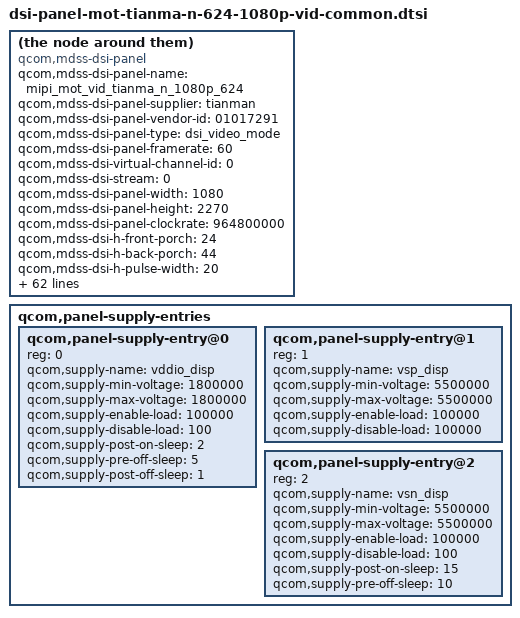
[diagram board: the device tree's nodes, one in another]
/* Copyright (c) 2016, The Linux Foundation. All rights reserved.
 *
 * This program is free software; you can redistribute it and/or modify
 * it under the terms of the GNU General Public License version 2 and
 * only version 2 as published by the Free Software Foundation.
 *
 * This program is distributed in the hope that it will be useful,
 * but WITHOUT ANY WARRANTY; without even the implied warranty of
 * MERCHANTABILITY or FITNESS FOR A PARTICULAR PURPOSE.  See the
 * GNU General Public License for more details.
 */

compatible = "qcom,mdss-dsi-panel";
qcom,mdss-dsi-panel-name = "mipi_mot_vid_tianma_n_1080p_624";
qcom,mdss-dsi-panel-supplier = "tianman";
qcom,mdss-dsi-panel-vendor-id = "01017291";
qcom,mdss-dsi-panel-type = "dsi_video_mode";
qcom,mdss-dsi-panel-framerate = <60>;
qcom,mdss-dsi-virtual-channel-id = <0>;
qcom,mdss-dsi-stream = <0>;
qcom,mdss-dsi-panel-width = <1080>;
qcom,mdss-dsi-panel-height = <2270>;
qcom,mdss-dsi-panel-clockrate = <964800000>;
qcom,mdss-dsi-h-front-porch = <24>;
qcom,mdss-dsi-h-back-porch = <44>;
qcom,mdss-dsi-h-pulse-width = <20>;
qcom,mdss-dsi-h-sync-skew = <0>;
qcom,mdss-dsi-v-front-porch = <14>;
qcom,mdss-dsi-v-back-porch = <8>;
qcom,mdss-dsi-v-pulse-width = <2>;
qcom,mdss-dsi-h-left-border = <0>;
qcom,mdss-dsi-h-right-border = <0>;
qcom,mdss-dsi-v-top-border = <0>;
qcom,mdss-dsi-v-bottom-border = <0>;
qcom,mdss-dsi-bpp = <24>;
qcom,mdss-dsi-underflow-color = <0xff>;
qcom,mdss-dsi-border-color = <0>;
qcom,mdss-dsi-on-command = [
	15 00 00 00 00 00 02 FF 23
	15 00 00 00 00 00 02 FB 01
        //resolution 1080*2270
	15 00 00 00 00 00 02 11 01
	15 00 00 00 00 00 02 12 7F
	15 00 00 00 00 00 02 15 6E
	15 00 00 00 00 00 02 16 0B
        //UI mode
	15 00 00 00 00 00 02 30 ff
	15 00 00 00 00 00 02 31 fe
	15 00 00 00 00 00 02 32 fc
	15 00 00 00 00 00 02 33 f8
	15 00 00 00 00 00 02 34 e5
	15 00 00 00 00 00 02 35 e0
	15 00 00 00 00 00 02 36 dc
	15 00 00 00 00 00 02 37 d8
	15 00 00 00 00 00 02 38 d8
	15 00 00 00 00 00 02 39 d8
	15 00 00 00 00 00 02 3A d8
	15 00 00 00 00 00 02 3B d8
	15 00 00 00 00 00 02 3D d8
	15 00 00 00 00 00 02 3F d8
	15 00 00 00 00 00 02 40 d8
	15 00 00 00 00 00 02 41 d8
        //STILL mode
	15 00 00 00 00 00 02 45 FF
	15 00 00 00 00 00 02 46 Fc
	15 00 00 00 00 00 02 47 F8
	15 00 00 00 00 00 02 48 ee
	15 00 00 00 00 00 02 49 e4
	15 00 00 00 00 00 02 4A da
	15 00 00 00 00 00 02 4B cf
	15 00 00 00 00 00 02 4C c9
	15 00 00 00 00 00 02 4D c9
	15 00 00 00 00 00 02 4E c9
	15 00 00 00 00 00 02 4F c9
	15 00 00 00 00 00 02 50 c9
	15 00 00 00 00 00 02 51 c9
	15 00 00 00 00 00 02 52 c9
	15 00 00 00 00 00 02 53 c9
	15 00 00 00 00 00 02 54 c9
        //MOVING mode
	15 00 00 00 00 00 02 58 FF
	15 00 00 00 00 00 02 59 f9
	15 00 00 00 00 00 02 5A F2
	15 00 00 00 00 00 02 5B e4
	15 00 00 00 00 00 02 5C d4
	15 00 00 00 00 00 02 5D cd
	15 00 00 00 00 00 02 5E b5
	15 00 00 00 00 00 02 5F af
	15 00 00 00 00 00 02 60 af
	15 00 00 00 00 00 02 61 af
	15 00 00 00 00 00 02 62 af
	15 00 00 00 00 00 02 63 af
	15 00 00 00 00 00 02 64 af
	15 00 00 00 00 00 02 65 af
	15 00 00 00 00 00 02 66 af
	15 00 00 00 00 00 02 67 af

	15 00 00 00 00 00 02 FF 25
	15 00 00 00 00 00 02 FB 01
	15 00 00 00 00 00 02 05 04
	15 00 00 00 00 00 02 FF F0
	15 00 00 00 00 00 02 FB 01
	15 01 00 00 00 00 02 A2 00
	15 01 00 00 00 00 02 FF 10
	05 01 00 00 00 00 02 29 00
	05 01 00 00 50 00 02 11 00

	15 01 00 00 00 00 02 FF 23
	15 01 00 00 00 00 02 FB 01
	15 01 00 00 00 00 02 00 80
	15 01 00 00 00 00 02 07 00
	15 01 00 00 00 00 02 08 01
	15 01 00 00 00 00 02 09 00

	15 01 00 00 00 00 02 FF 10
	15 01 00 00 00 00 02 FB 01
	39 01 00 00 00 00 03 51 00 00

	15 01 00 00 00 00 02 FF 10
	15 01 00 00 00 00 02 FB 01
	15 01 00 00 00 00 02 53 2C
	15 01 00 00 00 00 02 55 01
	39 01 00 00 00 00 03 68 04 01];/* display on */
qcom,mdss-dsi-off-command = [
	05 01 00 00 23 00 01 28		/* display_off */
	05 01 00 00 78 00 01 10];	/* enter sleep mode */


qcom,mdss-dsi-on-command-state = "dsi_lp_mode";
qcom,mdss-dsi-off-command-state = "dsi_lp_mode";

qcom,mdss-dsi-cabc-ui-command = [15 01 00 00 00 00 02 55 01];
qcom,mdss-dsi-cabc-ui-command-state = "dsi_hs_mode";
qcom,mdss-dsi-cabc-mv-command = [15 01 00 00 00 00 02 55 03];
qcom,mdss-dsi-cabc-mv-command-state = "dsi_hs_mode";
qcom,mdss-dsi-cabc-dis-command = [15 01 00 00 00 00 02 55 00];
qcom,mdss-dsi-cabc-dis-command-state = "dsi_hs_mode";

qcom,mdss-dsi-h-sync-pulse = <0>;
qcom,mdss-dsi-traffic-mode = "burst_mode";
qcom,mdss-dsi-bllp-eof-power-mode;
qcom,mdss-dsi-bllp-power-mode;
qcom,mdss-dsi-lane-0-state;
qcom,mdss-dsi-lane-1-state;
qcom,mdss-dsi-lane-2-state;
qcom,mdss-dsi-lane-3-state;
qcom,mdss-dsi-panel-timings-phy-v2 = [25 20 08 0a 06 03 04 a0
	25 20 08 0a 06 03 04 a0
	25 20 08 0a 06 03 04 a0
	25 20 08 0a 06 03 04 a0
	25 1d 08 0a 06 03 04 a0];
qcom,mdss-dsi-t-clk-post = <0x0e>;
qcom,mdss-dsi-t-clk-pre = <0x33>;
qcom,bklt-dcs-2bytes-enabled;
qcom,mdss-dsi-bl-min-level = <1>;
qcom,mdss-dsi-bl-max-level = <4095>;
qcom,mdss-dsi-dma-trigger = "trigger_sw";
qcom,mdss-dsi-mdp-trigger = "none";
qcom,mdss-dsi-bl-pmic-control-type = "bl_ctrl_dcs";
qcom,mdss-dsi-reset-sequence = <0 5>, <1 5>, <0 1>, <1 10>;
qcom,mdss-dsi-lp11-init;
qcom,mdss-dsi-tx-eot-append;
qcom,mdss-dsi-no-panel-on-read-support;
qcom,mdss-panel-off-rst-disable;

//qcom,esd-check-enabled;
qcom,mdss-dsi-panel-status-check-mode = "reg_read";
qcom,mdss-dsi-panel-status-read-length = <1>;
qcom,mdss-dsi-panel-status-command = [06 01 00 01 00 00 01 0A];
qcom,mdss-dsi-panel-status-command-state = "dsi_hs_mode";
qcom,mdss-dsi-panel-status-value = <0x9c>;

qcom,panel-supply-entries {
	#address-cells = <1>;
	#size-cells = <0>;

	qcom,panel-supply-entry@0 {
		reg = <0>;
		qcom,supply-name = "vddio_disp";
		qcom,supply-min-voltage = <1800000>;
		qcom,supply-max-voltage = <1800000>;
		qcom,supply-enable-load = <100000>;
		qcom,supply-disable-load = <100>;
		qcom,supply-post-on-sleep = <2>;
		qcom,supply-pre-off-sleep = <5>;
		qcom,supply-post-off-sleep = <1>;
	};

	qcom,panel-supply-entry@1 {
		reg = <1>;
		qcom,supply-name = "vsp_disp";
		qcom,supply-min-voltage = <5500000>;
		qcom,supply-max-voltage = <5500000>;
		qcom,supply-enable-load = <100000>;
		qcom,supply-disable-load = <100000>;
	};

	qcom,panel-supply-entry@2 {
		reg = <2>;
		qcom,supply-name = "vsn_disp";
		qcom,supply-min-voltage = <5500000>;
		qcom,supply-max-voltage = <5500000>;
		qcom,supply-enable-load = <100000>;
		qcom,supply-disable-load = <100>;
		qcom,supply-post-on-sleep = <15>;
		qcom,supply-pre-off-sleep = <10>;
	};
};
